VERSION ""

NS_ :

BS_:

BU_: XXX

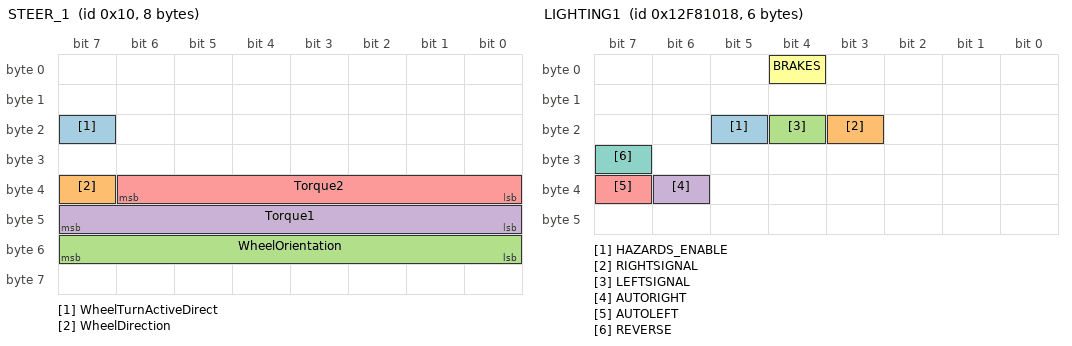
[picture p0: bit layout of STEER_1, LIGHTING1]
BO_ 16 STEER_1: 8 XXX
 SG_ WheelTurnActiveDirect : 23|1@0+ (1,0) [0|255] "" XXX
 SG_ WheelDirection : 39|1@0+ (1,0) [0|1] "" XXX
 SG_ WheelOrientation : 55|8@0+ (1,0) [0|255] "" XXX
 SG_ Torque1 : 40|8@1+ (1,0) [0|255] "" XXX
 SG_ Torque2 : 38|7@0+ (1,0) [0|127] "" XXX

BO_ 516 GAS: 8 XXX
 SG_ UserGasPosition : 1|18@0+ (1,0) [0|65535] "" XXX

BO_ 125 BRAKE1: 8 XXX
 SG_ PedalPosition : 7|16@0+ (1,0) [0|65535] "" XXX

BO_ 318246936 LIGHTING1: 6 XXX
 SG_ HAZARDS_ENABLE : 21|1@0+ (1,0) [0|1] "" XXX
 SG_ RIGHTSIGNAL : 19|1@0+ (1,0) [0|1] "" XXX
 SG_ LEFTSIGNAL : 20|1@0+ (1,0) [0|3] "" XXX
 SG_ AUTORIGHT : 38|1@0+ (1,0) [0|1] "" XXX
 SG_ AUTOLEFT : 39|1@0+ (1,0) [0|1] "" XXX
 SG_ BRAKES : 4|1@0+ (1,0) [0|1] "" XXX
 SG_ REVERSE : 31|1@0+ (1,0) [0|1] "" XXX

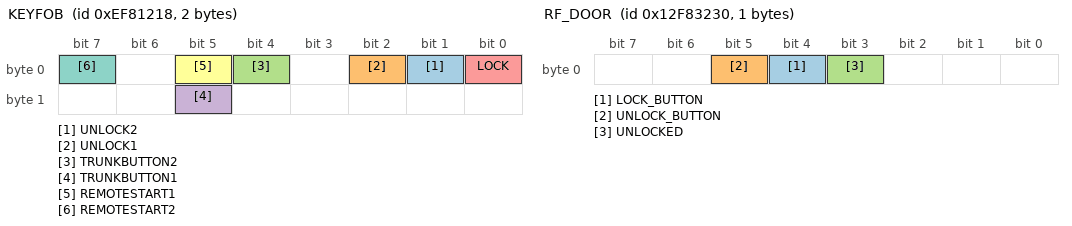
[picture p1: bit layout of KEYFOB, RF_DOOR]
BO_ 251138584 KEYFOB: 2 XXX
 SG_ UNLOCK2 : 1|1@0+ (1,0) [0|1] "" XXX
 SG_ UNLOCK1 : 2|1@0+ (1,0) [0|1] "" XXX
 SG_ TRUNKBUTTON2 : 4|1@0+ (1,0) [0|1] "" XXX
 SG_ TRUNKBUTTON1 : 13|1@0+ (1,0) [0|1] "" XXX
 SG_ LOCK : 0|1@0+ (1,0) [0|1] "" XXX
 SG_ REMOTESTART1 : 5|1@0+ (1,0) [0|1] "" XXX
 SG_ REMOTESTART2 : 7|1@0+ (1,0) [0|1] "" XXX

BO_ 318255664 RF_DOOR: 1 XXX
 SG_ LOCK_BUTTON : 4|1@0+ (1,0) [0|1] "" XXX
 SG_ UNLOCK_BUTTON : 5|1@0+ (1,0) [0|1] "" XXX
 SG_ UNLOCKED : 3|1@0+ (1,0) [0|1] "" XXX

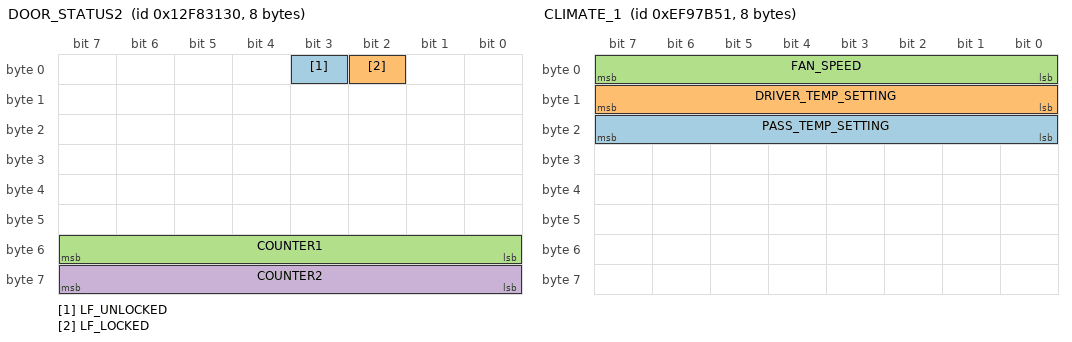
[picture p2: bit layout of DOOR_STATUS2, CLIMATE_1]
BO_ 318255408 DOOR_STATUS2: 8 XXX
 SG_ LF_UNLOCKED : 3|1@0+ (1,0) [0|1] "" XXX
 SG_ LF_LOCKED : 2|1@0+ (1,0) [0|1] "" XXX
 SG_ COUNTER1 : 48|8@1+ (1,0) [0|255] "" XXX
 SG_ COUNTER2 : 56|8@1+ (1,0) [0|255] "" XXX

BO_ 184057368 LIGHTING2: 3 XXX

BO_ 318264400 LIGHTING3: 8 XXX
 SG_ PARKING_LIGHTS : 6|1@0+ (1,0) [0|1] "" XXX

BO_ 184029464 LIGHTING4: 6 XXX

BO_ 184053784 LIGHTING_STALK1: 3 XXX

BO_ 318259736 RR_DOOR: 1 XXX
 SG_ UNLOCKED : 7|1@0+ (1,0) [0|1] "" XXX

BO_ 318288034 HEATED_SEATS: 2 XXX
 SG_ PASS_SEAT : 2|2@0+ (1,0) [0|3] "" XXX
 SG_ DRIVER_SEAT : 6|2@0+ (1,0) [0|3] "" XXX

BO_ 251231057 CLIMATE_1: 8 XXX
 SG_ PASS_TEMP_SETTING : 16|8@1+ (1,0) [0|255] "" XXX
 SG_ DRIVER_TEMP_SETTING : 8|8@1+ (1,0) [0|255] "" XXX
 SG_ FAN_SPEED : 0|8@1+ (1,0) [0|255] "" XXX

BO_ 251142168 DOOR_LOCKS: 1 XXX
 SG_ LOCKACTION_STATUS : 7|2@0+ (1,0) [0|1] "" XXX

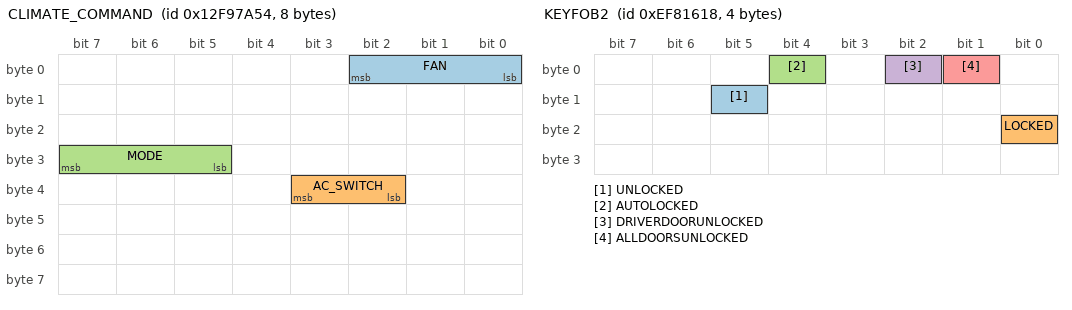
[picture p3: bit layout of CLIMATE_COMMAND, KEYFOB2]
BO_ 318339668 CLIMATE_COMMAND: 8 XXX
 SG_ FAN : 0|3@1+ (1,0) [0|7] "" XXX
 SG_ AC_SWITCH : 34|2@1+ (1,0) [0|3] "" XXX
 SG_ MODE : 31|3@0+ (1,0) [0|7] "" XXX

BO_ 251139608 KEYFOB2: 4 XXX
 SG_ UNLOCKED : 13|1@0+ (1,0) [0|1] "" XXX
 SG_ LOCKED : 16|1@0+ (1,0) [0|1] "" XXX
 SG_ AUTOLOCKED : 4|1@0+ (1,0) [0|1] "" XXX
 SG_ DRIVERDOORUNLOCKED : 2|1@0+ (1,0) [0|1] "" XXX
 SG_ ALLDOORSUNLOCKED : 1|1@0+ (1,0) [0|1] "" XXX

BO_ 318260272 FRONT_WINDOWS: 2 XXX
 SG_ RF_WINDOWSTATE : 14|1@0+ (1,0) [0|1] "" XXX
 SG_ LF_WINDOWSTATE : 15|1@0+ (1,0) [0|1] "" XXX

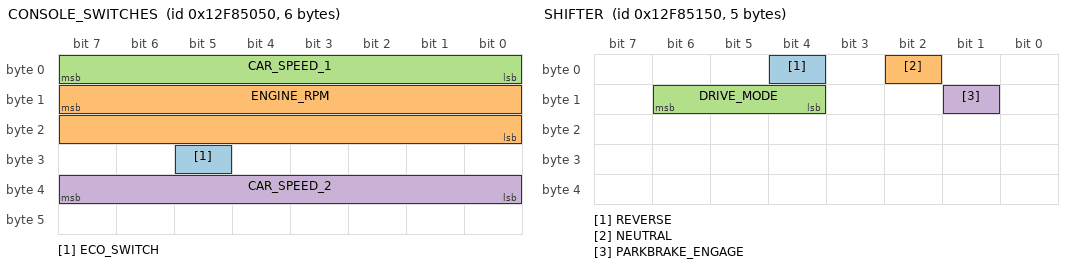
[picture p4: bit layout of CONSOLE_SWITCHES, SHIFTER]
BO_ 318263376 CONSOLE_SWITCHES: 6 XXX
 SG_ ECO_SWITCH : 29|1@0+ (1,0) [0|1] "" XXX
 SG_ ENGINE_RPM : 15|16@0+ (1,0) [0|65535] "" XXX
 SG_ CAR_SPEED_1 : 7|8@0+ (1,0) [0|255] "" XXX
 SG_ CAR_SPEED_2 : 32|8@1+ (1,0) [0|255] "" XXX

BO_ 318263632 SHIFTER: 5 XXX
 SG_ REVERSE : 4|1@0+ (1,0) [0|1] "" XXX
 SG_ NEUTRAL : 2|1@0+ (1,0) [0|1] "" XXX
 SG_ DRIVE_MODE : 14|3@0+ (1,0) [0|7] "" XXX
 SG_ PARKBRAKE_ENGAGE : 9|1@0+ (1,0) [0|1] "" XXX

BO_ 318337360 STEERING1: 3 XXX
 SG_ BOH1 : 7|8@0+ (1,0) [0|255] "" XXX
 SG_ STEER_ANGLE_COARSE : 15|16@0- (1,0) [0|255] "" XXX

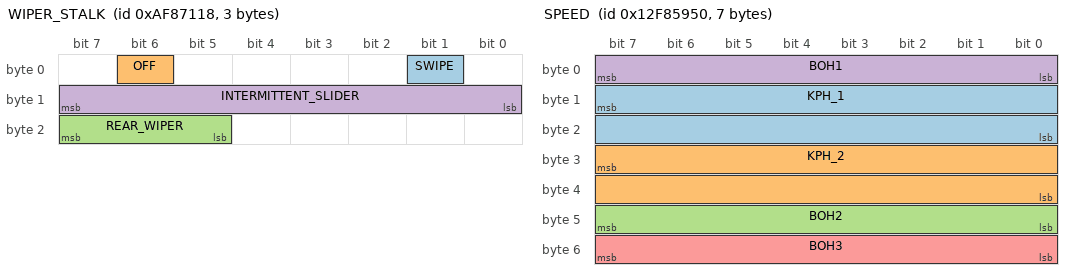
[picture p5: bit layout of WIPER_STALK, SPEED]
BO_ 184054040 WIPER_STALK: 3 XXX
 SG_ SWIPE : 1|1@0+ (1,0) [0|1] "" XXX
 SG_ OFF : 6|1@0+ (1,0) [0|1] "" XXX
 SG_ REAR_WIPER : 23|3@0+ (1,0) [0|7] "" XXX
 SG_ INTERMITTENT_SLIDER : 15|8@0+ (1,0) [0|255] "" XXX

BO_ 318265680 SPEED: 7 XXX
 SG_ KPH_1 : 15|16@0+ (0.01,0) [0|65535] "" XXX
 SG_ KPH_2 : 31|16@0+ (0.01,0) [0|65535] "" XXX
 SG_ BOH2 : 47|8@0+ (1,0) [0|255] "" XXX
 SG_ BOH1 : 7|8@0+ (1,0) [0|255] "" XXX
 SG_ BOH3 : 55|8@0+ (1,0) [0|255] "" XXX

BO_ 318303316 MAYBE_2: 8 XXX

BO_ 318259480 LR_DOOR: 1 XXX
 SG_ UNLOCKED : 7|1@0+ (1,0) [0|1] "" XXX

BO_ 318259224 RIGHT_DOORS: 1 XXX
 SG_ RF_OPEN : 6|1@0+ (1,0) [0|1] "" XXX
 SG_ RR_OPEN : 4|1@0+ (1,0) [0|1] "" XXX

BO_ 318255128 LEFT_DOORS: 1 XXX
 SG_ LR_OPEN : 5|1@0+ (1,0) [0|1] "" XXX
 SG_ LF_OPEN : 7|1@0+ (1,0) [0|1] "" XXX

BO_ 318275608 TRUNK: 1 XXX
 SG_ RELEASE_BUTTON : 7|1@0+ (1,0) [0|1] "" XXX

BO_ 318259992 HATCH: 1 XXX
 SG_ TRUNK_OPEN : 7|1@0+ (1,0) [0|1] "" XXX

BO_ 385449300 NEW_MSG_2: 8 XXX
 SG_ NEW_SIGNAL_1 : 48|8@1+ (1,0) [0|255] "" XXX
 SG_ NEW_SIGNAL_2 : 56|8@1+ (1,0) [0|255] "" XXX

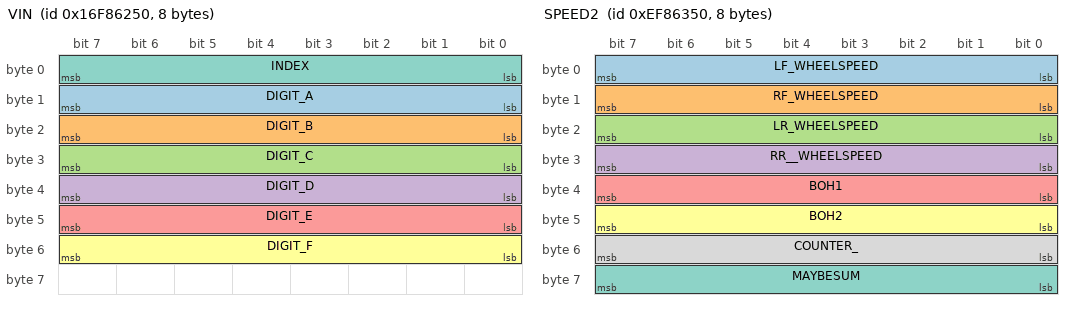
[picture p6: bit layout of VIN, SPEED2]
BO_ 385376848 VIN: 8 XXX
 SG_ DIGIT_A : 15|8@0+ (1,0) [0|255] "" XXX
 SG_ DIGIT_B : 23|8@0+ (1,0) [0|255] "" XXX
 SG_ DIGIT_C : 31|8@0+ (1,0) [0|255] "" XXX
 SG_ DIGIT_D : 39|8@0+ (1,0) [0|255] "" XXX
 SG_ DIGIT_E : 47|8@0+ (1,0) [0|255] "" XXX
 SG_ DIGIT_F : 55|8@0+ (1,0) [0|255] "" XXX
 SG_ INDEX : 7|8@0+ (1,0) [0|255] "" XXX

BO_ 251159376 SPEED2: 8 XXX
 SG_ LF_WHEELSPEED : 0|8@1+ (1,0) [0|255] "" XXX
 SG_ RF_WHEELSPEED : 8|8@1+ (1,0) [0|255] "" XXX
 SG_ LR_WHEELSPEED : 16|8@1+ (1,0) [0|255] "" XXX
 SG_ RR__WHEELSPEED : 24|8@1+ (1,0) [0|255] "" XXX
 SG_ BOH1 : 39|8@0+ (1,0) [0|255] "" XXX
 SG_ BOH2 : 47|8@0+ (1,0) [0|255] "" XXX
 SG_ MAYBESUM : 63|8@0+ (1,0) [0|255] "" XXX
 SG_ COUNTER_ : 55|8@0+ (1,0) [0|255] "" XXX

BO_ 251234897 NEW_MSG_3: 8 XXX
 SG_ NEW_SIGNAL_1 : 7|8@0+ (1,0) [0|255] "" XXX
 SG_ NEW_SIGNAL_2 : 15|8@0+ (1,0) [0|255] "" XXX

BO_ 318338128 STEERING2: 2 XXX
 SG_ NEW_SIGNAL_2 : 15|8@0+ (1,0) [0|255] "" XXX
 SG_ STEER_ANGLE_FINE : 7|8@0+ (1,0) [0|255] "" XXX

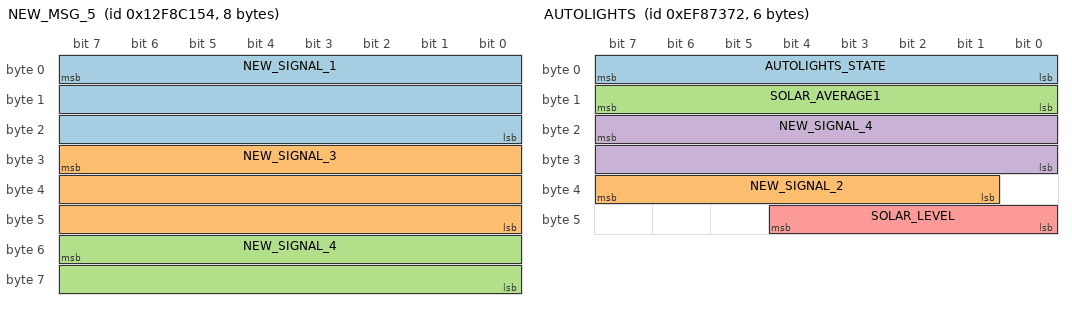
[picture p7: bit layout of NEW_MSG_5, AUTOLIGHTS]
BO_ 318292308 NEW_MSG_5: 8 XXX
 SG_ NEW_SIGNAL_1 : 7|24@0+ (1,0) [0|65535] "" XXX
 SG_ NEW_SIGNAL_3 : 31|24@0+ (1,0) [0|65535] "" XXX
 SG_ NEW_SIGNAL_4 : 55|16@0+ (1,0) [0|65535] "" XXX

BO_ 318263888 NEW_MSG_6: 8 XXX
 SG_ NEW_SIGNAL_1 : 7|8@0+ (1,0) [0|255] "" XXX

BO_ 251163506 AUTOLIGHTS: 6 XXX
 SG_ AUTOLIGHTS_STATE : 7|8@0+ (1,0) [0|255] "" XXX
 SG_ NEW_SIGNAL_2 : 33|7@1+ (1,0) [0|255] "" XXX
 SG_ SOLAR_AVERAGE1 : 15|8@0+ (1,0) [0|255] "" XXX
 SG_ NEW_SIGNAL_4 : 23|16@0+ (1,0) [0|255] "" XXX
 SG_ SOLAR_LEVEL : 40|5@1- (1,0) [0|255] "" XXX

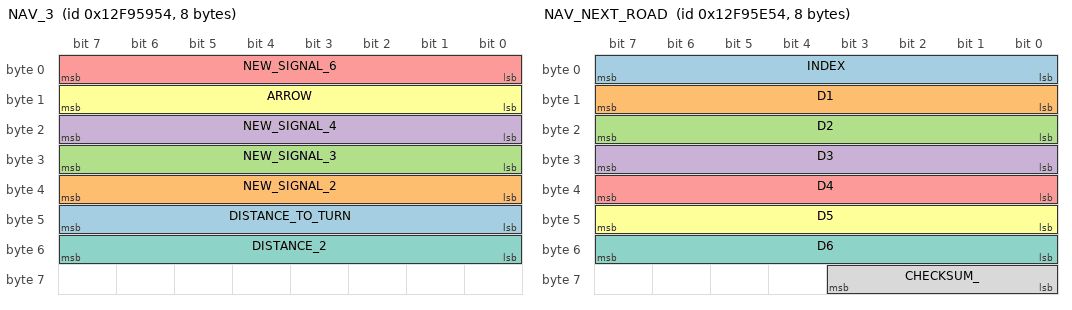
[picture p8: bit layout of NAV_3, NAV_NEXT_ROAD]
BO_ 318331220 NAV_3: 8 XXX
 SG_ DISTANCE_TO_TURN : 40|8@1+ (1,0) [0|255] "" XXX
 SG_ NEW_SIGNAL_2 : 32|8@1+ (1,0) [0|255] "" XXX
 SG_ NEW_SIGNAL_3 : 24|8@1+ (1,0) [0|255] "" XXX
 SG_ NEW_SIGNAL_4 : 16|8@1+ (1,0) [0|255] "" XXX
 SG_ NEW_SIGNAL_6 : 0|8@1+ (1,0) [0|255] "" XXX
 SG_ ARROW : 8|8@1+ (1,0) [0|255] "" XXX
 SG_ DISTANCE_2 : 48|8@1+ (1,0) [0|255] "" XXX

BO_ 318332500 NAV_NEXT_ROAD: 8 XXX
 SG_ INDEX : 7|8@0+ (1,0) [0|255] "" XXX
 SG_ D1 : 8|8@1+ (1,0) [0|255] "" XXX
 SG_ D2 : 16|8@1+ (1,0) [0|255] "" XXX
 SG_ D3 : 24|8@1+ (1,0) [0|255] "" XXX
 SG_ D4 : 32|8@1+ (1,0) [0|255] "" XXX
 SG_ D5 : 40|8@1+ (1,0) [0|255] "" XXX
 SG_ D6 : 48|8@1+ (1,0) [0|255] "" XXX
 SG_ CHECKSUM_ : 56|4@1+ (1,0) [0|255] "" XXX

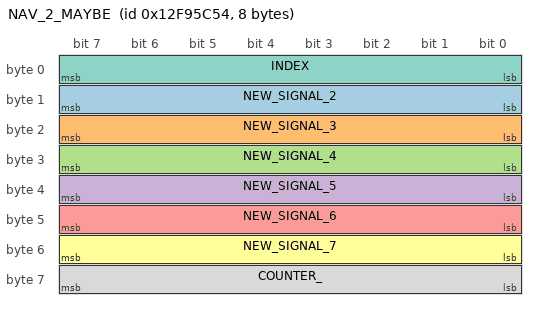
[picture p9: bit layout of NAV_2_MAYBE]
BO_ 318331988 NAV_2_MAYBE: 8 XXX
 SG_ NEW_SIGNAL_2 : 15|8@0+ (1,0) [0|255] "" XXX
 SG_ NEW_SIGNAL_3 : 23|8@0+ (1,0) [0|255] "" XXX
 SG_ NEW_SIGNAL_4 : 31|8@0+ (1,0) [0|255] "" XXX
 SG_ NEW_SIGNAL_5 : 39|8@0+ (1,0) [0|255] "" XXX
 SG_ NEW_SIGNAL_6 : 47|8@0+ (1,0) [0|255] "" XXX
 SG_ NEW_SIGNAL_7 : 55|8@0+ (1,0) [0|255] "" XXX
 SG_ INDEX : 0|8@1+ (1,0) [0|255] "" XXX
 SG_ COUNTER_ : 63|8@0+ (1,0) [0|255] "" XXX

BO_ 318332752 NAV_4: 8 XXX
 SG_ NEW_SIGNAL_1 : 23|8@0+ (1,0) [0|255] "" XXX

CM_ SG_ 16 WheelTurnActiveDirect "0-wheel going ccw,1-wheel going cw";
CM_ SG_ 16 WheelDirection "0-left,1-right. ";
CM_ SG_ 318264400 PARKING_LIGHTS "0 = OFF, 1 = ON";
CM_ SG_ 318288034 PASS_SEAT "0 = OFF, 1 = HIGH, 2 = MED, 3 = LO";
CM_ SG_ 318288034 DRIVER_SEAT "0 = OFF, 1 = HIGH, 2 = MED, 3 = LO";
CM_ SG_ 251231057 PASS_TEMP_SETTING "04 = HIGH, 08 = LO";
CM_ SG_ 251231057 DRIVER_TEMP_SETTING "04 = HIGH, 08 = LO";
CM_ SG_ 251231057 FAN_SPEED "en = current n setting, 6n = going to n setting";
CM_ SG_ 251142168 LOCKACTION_STATUS "0 = IDLE, 1 = UNLOCKING, 2 = LOCKING";
CM_ SG_ 318339668 MODE "5 = FACE, 4 = MIX, 3 = FLOOR, 2 = FLOOR_DEFROST";
CM_ SG_ 318260272 RF_WINDOWSTATE "1 = CLOSED, 0 = OPEN";
CM_ SG_ 318260272 LF_WINDOWSTATE "1 = CLOSED, 0 = OPEN";
CM_ SG_ 318263632 DRIVE_MODE "0 = DRIVE, 4 = S, 1 = L";
CM_ SG_ 184054040 REAR_WIPER "0 = OFF, 4 = INT, 1 = ON";
